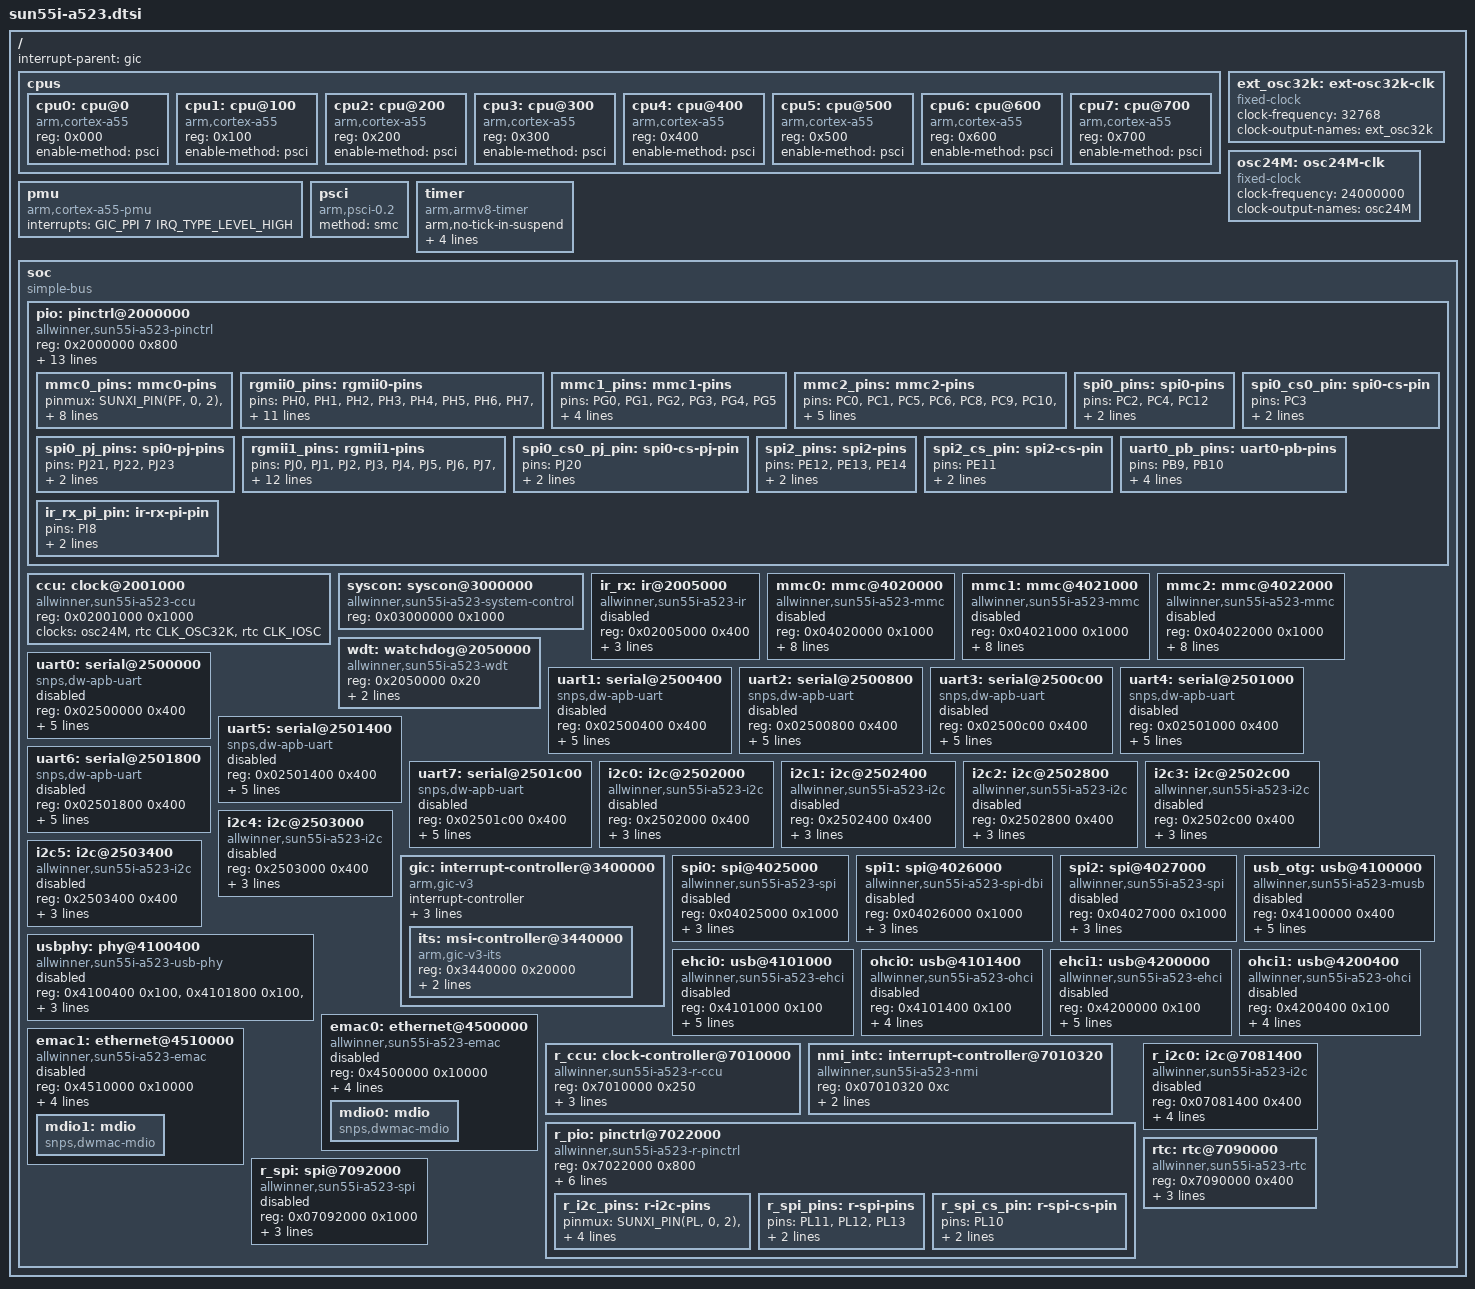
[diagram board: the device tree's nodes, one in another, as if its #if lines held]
// SPDX-License-Identifier: (GPL-2.0-only OR MIT)
// Copyright (C) 2023-2024 Arm Ltd.

#include <dt-bindings/interrupt-controller/arm-gic.h>
#include <dt-bindings/clock/sun6i-rtc.h>
#include <dt-bindings/clock/sun55i-a523-ccu.h>
#include <dt-bindings/clock/sun55i-a523-r-ccu.h>
#include <dt-bindings/reset/sun55i-a523-ccu.h>
#include <dt-bindings/reset/sun55i-a523-r-ccu.h>

#define SUNXI_PIN(port, pin, mux)	((pin) * 16 + (mux))

/ {
	interrupt-parent = <&gic>;
	#address-cells = <2>;
	#size-cells = <2>;

	cpus {
		#address-cells = <1>;
		#size-cells = <0>;

		cpu0: cpu@0 {
			compatible = "arm,cortex-a55";
			device_type = "cpu";
			reg = <0x000>;
#ifdef SUNXI_PSCI
			enable-method = "psci";
//			clocks = <&cpuclk CLK_CPU_L>;
		};

		cpu1: cpu@100 {
			compatible = "arm,cortex-a55";
			device_type = "cpu";
			reg = <0x100>;
			enable-method = "psci";
//			clocks = <&cpuclk CLK_CPU_L>;
		};

		cpu2: cpu@200 {
			compatible = "arm,cortex-a55";
			device_type = "cpu";
			reg = <0x200>;
			enable-method = "psci";
//			clocks = <&cpuclk CLK_CPU_L>;
		};

		cpu3: cpu@300 {
			compatible = "arm,cortex-a55";
			device_type = "cpu";
			reg = <0x300>;
			enable-method = "psci";
//			clocks = <&cpuclk CLK_CPU_L>;
		};

		cpu4: cpu@400 {
			compatible = "arm,cortex-a55";
			device_type = "cpu";
			reg = <0x400>;
			enable-method = "psci";
//			clocks = <&cpuclk CLK_CPU_B>;
		};

		cpu5: cpu@500 {
			compatible = "arm,cortex-a55";
			device_type = "cpu";
			reg = <0x500>;
			enable-method = "psci";
//			clocks = <&cpuclk CLK_CPU_B>;
		};

		cpu6: cpu@600 {
			compatible = "arm,cortex-a55";
			device_type = "cpu";
			reg = <0x600>;
			enable-method = "psci";
//			clocks = <&cpuclk CLK_CPU_B>;
		};

		cpu7: cpu@700 {
			compatible = "arm,cortex-a55";
			device_type = "cpu";
			reg = <0x700>;
			enable-method = "psci";
//			clocks = <&cpuclk CLK_CPU_B>;
#endif
		};
	};

	ext_osc32k: ext-osc32k-clk {
		#clock-cells = <0>;
		compatible = "fixed-clock";
		clock-frequency = <32768>;
		clock-output-names = "ext_osc32k";
	};

	osc24M: osc24M-clk {
		#clock-cells = <0>;
		compatible = "fixed-clock";
		clock-frequency = <24000000>;
		clock-output-names = "osc24M";
	};

	pmu {
		compatible = "arm,cortex-a55-pmu";
		interrupts = <GIC_PPI 7 IRQ_TYPE_LEVEL_HIGH>;
	};

#ifdef SUNXI_PSCI
	psci {
		compatible = "arm,psci-0.2";
		method = "smc";
	};
#endif

	timer {
		compatible = "arm,armv8-timer";
		arm,no-tick-in-suspend;
		interrupts = <GIC_PPI 13 IRQ_TYPE_LEVEL_HIGH>,
			     <GIC_PPI 14 IRQ_TYPE_LEVEL_HIGH>,
			     <GIC_PPI 11 IRQ_TYPE_LEVEL_HIGH>,
			     <GIC_PPI 10 IRQ_TYPE_LEVEL_HIGH>;
	};

	soc {
		compatible = "simple-bus";
		#address-cells = <1>;
		#size-cells = <1>;
		ranges = <0x0 0x0 0x0 0x40000000>;

		pio: pinctrl@2000000 {
			compatible = "allwinner,sun55i-a523-pinctrl";
			reg = <0x2000000 0x800>;
			interrupts = <GIC_SPI 69 IRQ_TYPE_LEVEL_HIGH>,
				     <GIC_SPI 71 IRQ_TYPE_LEVEL_HIGH>,
				     <GIC_SPI 73 IRQ_TYPE_LEVEL_HIGH>,
				     <GIC_SPI 75 IRQ_TYPE_LEVEL_HIGH>,
				     <GIC_SPI 77 IRQ_TYPE_LEVEL_HIGH>,
				     <GIC_SPI 79 IRQ_TYPE_LEVEL_HIGH>,
				     <GIC_SPI 81 IRQ_TYPE_LEVEL_HIGH>,
				     <GIC_SPI 83 IRQ_TYPE_LEVEL_HIGH>,
				     <GIC_SPI 85 IRQ_TYPE_LEVEL_HIGH>,
				     <GIC_SPI 140 IRQ_TYPE_LEVEL_HIGH>;
			clocks = <&ccu CLK_APB1>, <&osc24M>, <&rtc CLK_OSC32K>;
			clock-names = "apb", "hosc", "losc";
			gpio-controller;
			#gpio-cells = <3>;
			interrupt-controller;
			#interrupt-cells = <3>;

			mmc0_pins: mmc0-pins {
				pinmux = <SUNXI_PIN(PF, 0, 2)>,
					 <SUNXI_PIN(PF, 1, 2)>,
					 <SUNXI_PIN(PF, 2, 2)>,
					 <SUNXI_PIN(PF, 3, 2)>,
					 <SUNXI_PIN(PF, 4, 2)>,
					 <SUNXI_PIN(PF, 5, 2)>;
				pins = "PF0" ,"PF1", "PF2", "PF3", "PF4", "PF5";
				allwinner,pinmux = <2>;
				function = "mmc0";
				drive-strength = <30>;
				bias-pull-up;
			};

			rgmii0_pins: rgmii0-pins {
				pins = "PH0", "PH1", "PH2", "PH3", "PH4", "PH5",
				       "PH6", "PH7", "PH9", "PH10", "PH14",
				       "PH15", "PH16", "PH17", "PH18";
				pinmux = <SUNXI_PIN(PH, 0, 5)>,
					 <SUNXI_PIN(PH, 1, 5)>,
					 <SUNXI_PIN(PH, 2, 5)>,
					 <SUNXI_PIN(PH, 3, 5)>,
					 <SUNXI_PIN(PH, 4, 5)>,
					 <SUNXI_PIN(PH, 5, 5)>,
					 <SUNXI_PIN(PH, 6, 5)>,
					 <SUNXI_PIN(PH, 7, 5)>,
					 <SUNXI_PIN(PH, 9, 5)>,
					 <SUNXI_PIN(PH, 10, 5)>,
					 <SUNXI_PIN(PH, 14, 5)>,
					 <SUNXI_PIN(PH, 15, 5)>,
					 <SUNXI_PIN(PH, 16, 5)>,
					 <SUNXI_PIN(PH, 17, 5)>,
					 <SUNXI_PIN(PH, 18, 5)>;
				allwinner,pinmux = <5>;
				function = "emac";
			};

			/omit-if-no-ref/
			mmc1_pins: mmc1-pins {
				pins = "PG0" ,"PG1", "PG2", "PG3", "PG4", "PG5";
				allwinner,pinmux = <2>;
				function = "mmc1";
				drive-strength = <30>;
				bias-pull-up;
			};

			mmc2_pins: mmc2-pins {
				pins = "PC0", "PC1" ,"PC5", "PC6", "PC8", "PC9",
				       "PC10", "PC11", "PC13", "PC14", "PC15",
				       "PC16";
				allwinner,pinmux = <3>;
				function = "mmc2";
				drive-strength = <40>;
				bias-pull-up;
			};

			spi0_pins: spi0-pins {
				pins = "PC2", "PC4", "PC12";
				allwinner,pinmux = <4>;
				function = "spi0";
			};

			spi0_cs0_pin: spi0-cs-pin {
				pins = "PC3";
				allwinner,pinmux = <4>;
				function = "spi0";
			};

			spi0_pj_pins: spi0-pj-pins {
				pins = "PJ21", "PJ22", "PJ23";
				allwinner,pinmux = <5>;
				function = "spi0";
			};

			rgmii1_pins: rgmii1-pins {
				pins = "PJ0", "PJ1", "PJ2", "PJ3", "PJ4", "PJ5",
				       "PJ6", "PJ7", "PJ8", "PJ9", "PJ10",
				       "PJ11", "PJ12", "PJ13", "PJ14", "PJ15";
				pinmux = <SUNXI_PIN(PJ, 0, 5)>,
					 <SUNXI_PIN(PJ, 1, 5)>,
					 <SUNXI_PIN(PJ, 2, 5)>,
					 <SUNXI_PIN(PJ, 3, 5)>,
					 <SUNXI_PIN(PJ, 4, 5)>,
					 <SUNXI_PIN(PJ, 5, 5)>,
					 <SUNXI_PIN(PJ, 6, 5)>,
					 <SUNXI_PIN(PJ, 7, 5)>,
					 <SUNXI_PIN(PJ, 8, 5)>,
					 <SUNXI_PIN(PJ, 9, 5)>,
					 <SUNXI_PIN(PJ, 10, 5)>,
					 <SUNXI_PIN(PJ, 11, 5)>,
					 <SUNXI_PIN(PJ, 12, 5)>,
					 <SUNXI_PIN(PJ, 13, 5)>,
					 <SUNXI_PIN(PJ, 14, 5)>,
					 <SUNXI_PIN(PJ, 15, 5)>;
				allwinner,pinmux = <5>;
				function = "emac";
			};

			spi0_cs0_pj_pin: spi0-cs-pj-pin {
				pins = "PJ20";
				allwinner,pinmux = <5>;
				function = "spi0";
			};

			spi2_pins: spi2-pins {
				pins = "PE12", "PE13", "PE14";
				allwinner,pinmux = <4>;
				function = "spi2";
			};

			spi2_cs_pin: spi2-cs-pin {
				pins = "PE11";
				allwinner,pinmux = <4>;
				function = "spi2";
			};

			uart0_pb_pins: uart0-pb-pins {
				pins = "PB9", "PB10";
				pinmux = <SUNXI_PIN(PB, 9, 2)>,
					 <SUNXI_PIN(PB, 10, 2)>;
				allwinner,pinmux = <2>;
				function = "uart0";
			};

			ir_rx_pi_pin: ir-rx-pi-pin {
				pins = "PI8";
				allwinner,pinmux = <3>;
				function = "ir_rx";
			};
		};

		ccu: clock@2001000 {
			compatible = "allwinner,sun55i-a523-ccu";
			reg = <0x02001000 0x1000>;
			clocks = <&osc24M>, <&rtc CLK_OSC32K>, <&rtc CLK_IOSC>;
			clock-names = "hosc", "losc", "iosc";
			#clock-cells = <1>;
			#reset-cells = <1>;
		};

		syscon: syscon@3000000 {
			compatible = "allwinner,sun55i-a523-system-control";
			reg = <0x03000000 0x1000>;
			#address-cells = <1>;
			#size-cells = <1>;
			ranges;
		};

		ir_rx: ir@2005000 {
			compatible = "allwinner,sun55i-a523-ir",
				     "allwinner,sun6i-a31-ir";
			reg = <0x02005000 0x400>;
			interrupts = <GIC_SPI 27 IRQ_TYPE_LEVEL_HIGH>;
			clocks = <&ccu CLK_BUS_IR_RX>,
				 <&ccu CLK_IR_RX>;
			clock-names = "apb", "ir";
			resets = <&ccu RST_BUS_IR_RX>;
			status = "disabled";
		};

		mmc0: mmc@4020000 {
			compatible = "allwinner,sun55i-a523-mmc",
				     "allwinner,sun20i-d1-mmc";
			reg = <0x04020000 0x1000>;
			clocks = <&ccu CLK_BUS_MMC0>, <&ccu CLK_MMC0>;
			clock-names = "ahb", "mmc";
			resets = <&ccu RST_BUS_MMC0>;
			reset-names = "ahb";
			interrupts = <GIC_SPI 40 IRQ_TYPE_LEVEL_HIGH>;
			pinctrl-names = "default";
			pinctrl-0 = <&mmc0_pins>;
			status = "disabled";

			max-frequency = <150000000>;
			cap-sd-highspeed;
			cap-mmc-highspeed;
			cap-sdio-irq;
			#address-cells = <1>;
			#size-cells = <0>;
		};

		mmc1: mmc@4021000 {
			compatible = "allwinner,sun55i-a523-mmc",
				     "allwinner,sun20i-d1-mmc";
			reg = <0x04021000 0x1000>;
			clocks = <&ccu CLK_BUS_MMC1>, <&ccu CLK_MMC1>;
			clock-names = "ahb", "mmc";
			resets = <&ccu RST_BUS_MMC1>;
			reset-names = "ahb";
			interrupts = <GIC_SPI 41 IRQ_TYPE_LEVEL_HIGH>;
			pinctrl-names = "default";
			pinctrl-0 = <&mmc1_pins>;
			status = "disabled";

			max-frequency = <150000000>;
			cap-sd-highspeed;
			cap-mmc-highspeed;
			cap-sdio-irq;
			#address-cells = <1>;
			#size-cells = <0>;
		};

		mmc2: mmc@4022000 {
			compatible = "allwinner,sun55i-a523-mmc",
				     "allwinner,sun20i-d1-mmc";
			reg = <0x04022000 0x1000>;
			clocks = <&ccu CLK_BUS_MMC2>, <&ccu CLK_MMC2>;
			clock-names = "ahb", "mmc";
			resets = <&ccu RST_BUS_MMC2>;
			reset-names = "ahb";
			interrupts = <GIC_SPI 42 IRQ_TYPE_LEVEL_HIGH>;
			pinctrl-names = "default";
			pinctrl-0 = <&mmc2_pins>;
			status = "disabled";

			max-frequency = <150000000>;
			cap-sd-highspeed;
			cap-mmc-highspeed;
			cap-sdio-irq;
			#address-cells = <1>;
			#size-cells = <0>;
		};

		wdt: watchdog@2050000 {
			compatible = "allwinner,sun55i-a523-wdt";
			reg = <0x2050000 0x20>;
			interrupts = <GIC_SPI 63 IRQ_TYPE_LEVEL_HIGH>;
			clocks = <&osc24M>, <&rtc CLK_OSC32K>;
			clock-names = "hosc", "losc";
			status = "okay";
		};

		uart0: serial@2500000 {
			compatible = "snps,dw-apb-uart";
			reg = <0x02500000 0x400>;
			interrupts = <GIC_SPI 2 IRQ_TYPE_LEVEL_HIGH>;
			reg-shift = <2>;
			reg-io-width = <4>;
			clocks = <&ccu CLK_BUS_UART0>;
			resets = <&ccu RST_BUS_UART0>;
			status = "disabled";
		};

		uart1: serial@2500400 {
			compatible = "snps,dw-apb-uart";
			reg = <0x02500400 0x400>;
			interrupts = <GIC_SPI 3 IRQ_TYPE_LEVEL_HIGH>;
			reg-shift = <2>;
			reg-io-width = <4>;
			clocks = <&ccu CLK_BUS_UART1>;
			resets = <&ccu RST_BUS_UART1>;
			status = "disabled";
		};

		uart2: serial@2500800 {
			compatible = "snps,dw-apb-uart";
			reg = <0x02500800 0x400>;
			interrupts = <GIC_SPI 4 IRQ_TYPE_LEVEL_HIGH>;
			reg-shift = <2>;
			reg-io-width = <4>;
			clocks = <&ccu CLK_BUS_UART2>;
			resets = <&ccu RST_BUS_UART2>;
			status = "disabled";
		};

		uart3: serial@2500c00 {
			compatible = "snps,dw-apb-uart";
			reg = <0x02500c00 0x400>;
			interrupts = <GIC_SPI 5 IRQ_TYPE_LEVEL_HIGH>;
			reg-shift = <2>;
			reg-io-width = <4>;
			clocks = <&ccu CLK_BUS_UART3>;
			resets = <&ccu RST_BUS_UART3>;
			status = "disabled";
		};

		uart4: serial@2501000 {
			compatible = "snps,dw-apb-uart";
			reg = <0x02501000 0x400>;
			interrupts = <GIC_SPI 6 IRQ_TYPE_LEVEL_HIGH>;
			reg-shift = <2>;
			reg-io-width = <4>;
			clocks = <&ccu CLK_BUS_UART4>;
			resets = <&ccu RST_BUS_UART4>;
			status = "disabled";
		};

		uart5: serial@2501400 {
			compatible = "snps,dw-apb-uart";
			reg = <0x02501400 0x400>;
			interrupts = <GIC_SPI 7 IRQ_TYPE_LEVEL_HIGH>;
			reg-shift = <2>;
			reg-io-width = <4>;
			clocks = <&ccu CLK_BUS_UART5>;
			resets = <&ccu RST_BUS_UART5>;
			status = "disabled";
		};

		uart6: serial@2501800 {
			compatible = "snps,dw-apb-uart";
			reg = <0x02501800 0x400>;
			interrupts = <GIC_SPI 8 IRQ_TYPE_LEVEL_HIGH>;
			reg-shift = <2>;
			reg-io-width = <4>;
			clocks = <&ccu CLK_BUS_UART6>;
			resets = <&ccu RST_BUS_UART6>;
			status = "disabled";
		};

		uart7: serial@2501c00 {
			compatible = "snps,dw-apb-uart";
			reg = <0x02501c00 0x400>;
			interrupts = <GIC_SPI 9 IRQ_TYPE_LEVEL_HIGH>;
			reg-shift = <2>;
			reg-io-width = <4>;
			clocks = <&ccu CLK_BUS_UART7>;
			resets = <&ccu RST_BUS_UART7>;
			status = "disabled";
		};

		i2c0: i2c@2502000 {
			compatible = "allwinner,sun55i-a523-i2c",
				     "allwinner,sun8i-v536-i2c",
				     "allwinner,sun6i-a31-i2c";
			reg = <0x2502000 0x400>;
			interrupts = <GIC_SPI 10 IRQ_TYPE_LEVEL_HIGH>;
			clocks = <&ccu CLK_BUS_I2C0>;
			resets = <&ccu RST_BUS_I2C0>;
//			dmas = <&dma 43>, <&dma 43>;
			dma-names = "rx", "tx";
			status = "disabled";
			#address-cells = <1>;
			#size-cells = <0>;
		};

		i2c1: i2c@2502400 {
			compatible = "allwinner,sun55i-a523-i2c",
				     "allwinner,sun8i-v536-i2c",
				     "allwinner,sun6i-a31-i2c";
			reg = <0x2502400 0x400>;
			interrupts = <GIC_SPI 11 IRQ_TYPE_LEVEL_HIGH>;
			clocks = <&ccu CLK_BUS_I2C1>;
			resets = <&ccu RST_BUS_I2C1>;
			status = "disabled";
			#address-cells = <1>;
			#size-cells = <0>;
		};

		i2c2: i2c@2502800 {
			compatible = "allwinner,sun55i-a523-i2c",
				     "allwinner,sun8i-v536-i2c",
				     "allwinner,sun6i-a31-i2c";
			reg = <0x2502800 0x400>;
			interrupts = <GIC_SPI 12 IRQ_TYPE_LEVEL_HIGH>;
			clocks = <&ccu CLK_BUS_I2C2>;
			resets = <&ccu RST_BUS_I2C2>;
			status = "disabled";
			#address-cells = <1>;
			#size-cells = <0>;
		};

		i2c3: i2c@2502c00 {
			compatible = "allwinner,sun55i-a523-i2c",
				     "allwinner,sun8i-v536-i2c",
				     "allwinner,sun6i-a31-i2c";
			reg = <0x2502c00 0x400>;
			interrupts = <GIC_SPI 13 IRQ_TYPE_LEVEL_HIGH>;
			clocks = <&ccu CLK_BUS_I2C3>;
			resets = <&ccu RST_BUS_I2C3>;
			status = "disabled";
			#address-cells = <1>;
			#size-cells = <0>;
		};

		i2c4: i2c@2503000 {
			compatible = "allwinner,sun55i-a523-i2c",
				     "allwinner,sun8i-v536-i2c",
				     "allwinner,sun6i-a31-i2c";
			reg = <0x2503000 0x400>;
			interrupts = <GIC_SPI 14 IRQ_TYPE_LEVEL_HIGH>;
			clocks = <&ccu CLK_BUS_I2C4>;
			resets = <&ccu RST_BUS_I2C4>;
			status = "disabled";
			#address-cells = <1>;
			#size-cells = <0>;
		};

		i2c5: i2c@2503400 {
			compatible = "allwinner,sun55i-a523-i2c",
				     "allwinner,sun8i-v536-i2c",
				     "allwinner,sun6i-a31-i2c";
			reg = <0x2503400 0x400>;
			interrupts = <GIC_SPI 15 IRQ_TYPE_LEVEL_HIGH>;
			clocks = <&ccu CLK_BUS_I2C5>;
			resets = <&ccu RST_BUS_I2C5>;
			status = "disabled";
			#address-cells = <1>;
			#size-cells = <0>;
		};

		gic: interrupt-controller@3400000 {
			compatible = "arm,gic-v3";
			#address-cells = <1>;
			#interrupt-cells = <3>;
			#size-cells = <1>;
			ranges;
			interrupt-controller;
			reg = <0x3400000 0x10000>,
			      <0x3460000 0x100000>;
			interrupts = <GIC_PPI 9 IRQ_TYPE_LEVEL_HIGH>;
			dma-noncoherent;

			its: msi-controller@3440000 {
				compatible = "arm,gic-v3-its";
				reg = <0x3440000 0x20000>;
				msi-controller;
				#msi-cells = <1>;
				dma-noncoherent;
			};
		};

		spi0: spi@4025000 {
			compatible = "allwinner,sun55i-a523-spi",
				     "allwinner,sun50i-r329-spi";
			reg = <0x04025000 0x1000>;
			interrupts = <GIC_SPI 16 IRQ_TYPE_LEVEL_HIGH>;
			clocks = <&ccu CLK_BUS_SPI0>, <&ccu CLK_SPI0>;
			clock-names = "ahb", "mod";
//			dmas = <&dma 22>, <&dma 22>;
			dma-names = "rx", "tx";
			resets = <&ccu RST_BUS_SPI0>;
			status = "disabled";
			#address-cells = <1>;
			#size-cells = <0>;
		};

		spi1: spi@4026000 {
                        compatible = "allwinner,sun55i-a523-spi-dbi",
				     "allwinner,sun50i-r329-spi-dbi",
				     "allwinner,sun50i-r329-spi";
			reg = <0x04026000 0x1000>;
			interrupts = <GIC_SPI 17 IRQ_TYPE_LEVEL_HIGH>;
			clocks = <&ccu CLK_BUS_SPI1>, <&ccu CLK_SPI1>;
			clock-names = "ahb", "mod";
//			dmas = <&dma 23>, <&dma 23>;
			dma-names = "rx", "tx";
			resets = <&ccu RST_BUS_SPI1>;
			status = "disabled";
			#address-cells = <1>;
			#size-cells = <0>;
		};

		spi2: spi@4027000 {
			compatible = "allwinner,sun55i-a523-spi",
				     "allwinner,sun50i-r329-spi";
			reg = <0x04027000 0x1000>;
			interrupts = <GIC_SPI 18 IRQ_TYPE_LEVEL_HIGH>;
			clocks = <&ccu CLK_BUS_SPI2>, <&ccu CLK_SPI2>;
			clock-names = "ahb", "mod";
//			dmas = <&dma 24>, <&dma 24>;
			dma-names = "rx", "tx";
			resets = <&ccu RST_BUS_SPI2>;
			status = "disabled";
			#address-cells = <1>;
			#size-cells = <0>;
		};

		usb_otg: usb@4100000 {
			compatible = "allwinner,sun55i-a523-musb",
				     "allwinner,sun8i-a33-musb";
			reg = <0x4100000 0x400>;
			interrupts = <GIC_SPI 29 IRQ_TYPE_LEVEL_HIGH>;
			interrupt-names = "mc";
			clocks = <&ccu CLK_BUS_OTG>;
			resets = <&ccu RST_BUS_OTG>;
			extcon = <&usbphy 0>;
			phys = <&usbphy 0>;
			phy-names = "usb";
			status = "disabled";
		};

		usbphy: phy@4100400 {
			compatible = "allwinner,sun55i-a523-usb-phy",
				     "allwinner,sun20i-d1-usb-phy";
			reg = <0x4100400 0x100>,
			      <0x4101800 0x100>,
			      <0x4200800 0x100>;
			reg-names = "phy_ctrl",
				    "pmu0",
				    "pmu1";
			clocks = <&osc24M>,
				 <&osc24M>;
			clock-names = "usb0_phy",
				      "usb1_phy";
			resets = <&ccu RST_USB_PHY0>,
				 <&ccu RST_USB_PHY1>;
			reset-names = "usb0_reset",
				      "usb1_reset";
			status = "disabled";
			#phy-cells = <1>;
		};

		ehci0: usb@4101000 {
			compatible = "allwinner,sun55i-a523-ehci",
				     "generic-ehci";
			reg = <0x4101000 0x100>;
			interrupts = <GIC_SPI 30 IRQ_TYPE_LEVEL_HIGH>;
			clocks = <&ccu CLK_BUS_OHCI0>,
				 <&ccu CLK_BUS_EHCI0>,
				 <&ccu CLK_USB_OHCI0>;
			resets = <&ccu RST_BUS_OHCI0>,
				 <&ccu RST_BUS_EHCI0>;
			phys = <&usbphy 0>;
			phy-names = "usb";
			status = "disabled";
		};

		ohci0: usb@4101400 {
			compatible = "allwinner,sun55i-a523-ohci",
				     "generic-ohci";
			reg = <0x4101400 0x100>;
			interrupts = <GIC_SPI 31 IRQ_TYPE_LEVEL_HIGH>;
			clocks = <&ccu CLK_BUS_OHCI0>,
				 <&ccu CLK_USB_OHCI0>;
			resets = <&ccu RST_BUS_OHCI0>;
			phys = <&usbphy 0>;
			phy-names = "usb";
			status = "disabled";
		};

		ehci1: usb@4200000 {
			compatible = "allwinner,sun55i-a523-ehci",
				     "generic-ehci";
			reg = <0x4200000 0x100>;
			interrupts = <GIC_SPI 32 IRQ_TYPE_LEVEL_HIGH>;
			clocks = <&ccu CLK_BUS_OHCI1>,
				 <&ccu CLK_BUS_EHCI1>,
				 <&ccu CLK_USB_OHCI1>;
			resets = <&ccu RST_BUS_OHCI1>,
				 <&ccu RST_BUS_EHCI1>;
			phys = <&usbphy 1>;
			phy-names = "usb";
			status = "disabled";
		};

		ohci1: usb@4200400 {
			compatible = "allwinner,sun55i-a523-ohci",
				     "generic-ohci";
			reg = <0x4200400 0x100>;
			interrupts = <GIC_SPI 33 IRQ_TYPE_LEVEL_HIGH>;
			clocks = <&ccu CLK_BUS_OHCI1>,
				 <&ccu CLK_USB_OHCI1>;
			resets = <&ccu RST_BUS_OHCI1>;
			phys = <&usbphy 1>;
			phy-names = "usb";
			status = "disabled";
		};

		emac0: ethernet@4500000 {
			compatible = "allwinner,sun55i-a523-emac",
				     "allwinner,sun50i-a64-emac";
			reg = <0x4500000 0x10000>;
			interrupts = <GIC_SPI 46 IRQ_TYPE_LEVEL_HIGH>;
			interrupt-names = "macirq";
			clocks = <&ccu CLK_BUS_EMAC0>;
			clock-names = "stmmaceth";
			resets = <&ccu RST_BUS_EMAC0>;
			reset-names = "stmmaceth";
			syscon = <&syscon>;
			status = "disabled";

			mdio0: mdio {
				compatible = "snps,dwmac-mdio";
				#address-cells = <1>;
				#size-cells = <0>;
			};
		};

		emac1: ethernet@4510000 {
			compatible = "allwinner,sun55i-a523-emac",
				     "allwinner,sun50i-a64-emac";
			reg = <0x4510000 0x10000>;
			interrupts = <GIC_SPI 47 IRQ_TYPE_LEVEL_HIGH>;
			interrupt-names = "macirq";
			clocks = <&ccu CLK_BUS_EMAC1>;	/* different */
			clock-names = "stmmaceth";
			resets = <&ccu RST_BUS_EMAC1>;	/* different */
			reset-names = "stmmaceth";
			syscon = <&syscon>;	/* + 0x04 */
			status = "disabled";

			mdio1: mdio {
				compatible = "snps,dwmac-mdio";
				#address-cells = <1>;
				#size-cells = <0>;
			};
		};

		r_ccu: clock-controller@7010000 {
			compatible = "allwinner,sun55i-a523-r-ccu";
			reg = <0x7010000 0x250>;
			clocks = <&osc24M>,
				 <&rtc CLK_OSC32K>,
				 <&rtc CLK_IOSC>,
				 <&ccu CLK_PLL_PERIPH0_200M>,
		/* This is wrong, it should be <&mcu_ccu CLK_PLL_AUDIO1_4X>; */
				 <&ccu CLK_PLL_AUDIO0_4X>;
			clock-names = "hosc",
				      "losc",
				      "iosc",
				      "pll-periph",
				      "pll-audio";
			#clock-cells = <1>;
			#reset-cells = <1>;
		};

		nmi_intc: interrupt-controller@7010320 {
			compatible = "allwinner,sun55i-a523-nmi",
				     "allwinner,sun9i-a80-nmi";
			reg = <0x07010320 0xc>;
			interrupt-controller;
			#interrupt-cells = <2>;
			interrupts = <GIC_SPI 148 IRQ_TYPE_LEVEL_HIGH>;
		};

		r_pio: pinctrl@7022000 {
			compatible = "allwinner,sun55i-a523-r-pinctrl";
			reg = <0x7022000 0x800>;
			interrupts = <GIC_SPI 159 IRQ_TYPE_LEVEL_HIGH>,
				     <GIC_SPI 161 IRQ_TYPE_LEVEL_HIGH>;
			clocks = <&r_ccu CLK_R_APB0>,
				 <&osc24M>,
				 <&rtc CLK_OSC32K>;
			clock-names = "apb", "hosc", "losc";
			gpio-controller;
			#gpio-cells = <3>;
			interrupt-controller;
			#interrupt-cells = <3>;

			r_i2c_pins: r-i2c-pins {
				pinmux = <SUNXI_PIN(PL, 0, 2)>,
					 <SUNXI_PIN(PL, 1, 2)>;
				pins = "PL0" ,"PL1";
				allwinner,pinmux = <2>;
				function = "r_i2c0";
			};

			r_spi_pins: r-spi-pins {
				pins = "PL11" ,"PL12", "PL13";
				allwinner,pinmux = <6>;
				function = "r_spi";
			};

			r_spi_cs_pin: r-spi-cs-pin {
				pins = "PL10";
				allwinner,pinmux = <6>;
				function = "r_spi";
			};
		};

		r_i2c0: i2c@7081400 {
			compatible = "allwinner,sun55i-a523-i2c",
				     "allwinner,sun8i-v536-i2c",
				     "allwinner,sun6i-a31-i2c";
			reg = <0x07081400 0x400>;
			interrupts = <GIC_SPI 164 IRQ_TYPE_LEVEL_HIGH>;
			clocks = <&r_ccu CLK_BUS_R_I2C0>;
//			dmas = <&dma 49>, <&dma 49>;
			dma-names = "rx", "tx";
			resets = <&r_ccu RST_BUS_R_I2C0>;
			pinctrl-names = "default";
			pinctrl-0 = <&r_i2c_pins>;
			status = "disabled";

			#address-cells = <1>;
			#size-cells = <0>;
		};

		rtc: rtc@7090000 {
			compatible = "allwinner,sun55i-a523-rtc",
				     "allwinner,sun50i-r329-rtc";
			reg = <0x7090000 0x400>;
			interrupts = <GIC_SPI 157 IRQ_TYPE_LEVEL_HIGH>;
			clocks = <&r_ccu CLK_BUS_R_RTC>,
				 <&osc24M>,
				 <&r_ccu CLK_R_AHB>;
			clock-names = "bus", "hosc", "ahb";
			#clock-cells = <1>;
		};

		r_spi: spi@7092000 {
			compatible = "allwinner,sun55i-a523-spi",
				     "allwinner,sun50i-r329-spi";
			reg = <0x07092000 0x1000>;
			interrupts = <GIC_SPI 172 IRQ_TYPE_LEVEL_HIGH>;
			clocks = <&r_ccu CLK_BUS_R_SPI>, <&r_ccu CLK_R_SPI>;
			clock-names = "ahb", "mod";
//			dmas = <&r_dma 13>, <&r_dma 13>;
			dma-names = "rx", "tx";
			resets = <&r_ccu RST_BUS_R_SPI>;
			status = "disabled";
			#address-cells = <1>;
			#size-cells = <0>;
		};
	};
};
